# STM32H730 register map
File version: 1.9
CPU: CM7 r0p1, little endian, MPU, FPU, 4 interrupt priority bits
Registers are 32-bit, read-write, reset 0x0 unless marked. A register's access mark holds for its fields unless they carry their own. Offsets are from the block's base; [hi:lo] are bit positions; {n}, {i} and the like mark numbered series; 'fields as' and 'values as' point back to an identical list.

## BDMA
Base 0x58025400
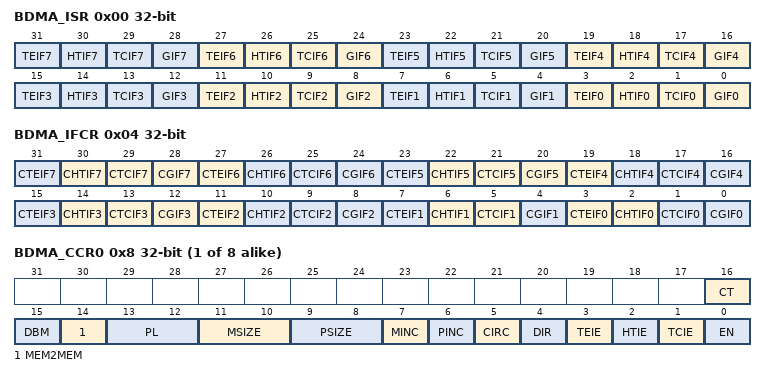
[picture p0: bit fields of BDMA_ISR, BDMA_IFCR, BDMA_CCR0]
0x00 BDMA_ISR ro — BDMA interrupt status register
  [4n+3] TEIF{n} (n=0..7) — transfer error (TE) flag for channel {n}
    0=no TE event; 1=a TE event occurred
  [4n+2] HTIF{n} (n=0..7) — half transfer (HT) flag for channel {n}
    0=no HT event; 1=a HT event occurred
  [4n+1] TCIF{n} (n=0..7) — transfer complete (TC) flag for channel {n}
    0=no TC event; 1=a TC event occurred
  [4n] GIF{n} (n=0..7) — global interrupt flag for channel {n}
    0=no TE, HT or TC event; 1=a TE, HT or TC event occurred
0x04 BDMA_IFCR wo — BDMA interrupt flag clear register
  [4n+3] CTEIF{n} (n=0..7) — transfer error flag clear for channel {n}
  [4n+2] CHTIF{n} (n=3..7) — half transfer flag clear for channel {n}
  [4n+1] CTCIF{n} (n=0..7) — transfer complete flag clear for channel {n}
  [4n] CGIF{n} (n=2..7) — global interrupt flag clear for channel {n}
  [10] CHTIF2 — half transfer flag clear for channe2
  [6] CHTIF1 — half transfer flag clear for channel 1
  [4] CGIF1 — global interrupt flag clear for channel 0
  [2] CHTIF0 — half transfer flag clear for channel 0
  [0] CGIF0 — global interrupt flag clear for channel 0
{0x8+0x14*i} BDMA_CCR{i} (i=0..7) — BDMA channel {i} configuration register
  [16] CT — current target memory of DMA transfer in double-buffer mode This bit is toggled by hardware at the end of each channel transfer in double-buffer mode. Note: this bit is set and cleared by software. It must not be written when the channel is enabled (EN = 1). It is read-only when the channel is enabled (EN = 1).
    0=memory 0 (addressed by the BDMA_CM0AR pointer); 1=memory 1 (addressed by the BDMA_CM1AR pointer)
  [15] DBM — double-buffer mode This bit must be set only in memory-to-peripheral and peripheral-to-memory transfers (MEM2MEM=0). The CIRC bit must also be set in double buffer mode. Note: this bit is set and cleared by software. It must not be written when the channel is enabled (EN = 1). It is not read-only when the channel is enabled (EN = 1).
    0=disabled (no memory address switch at the end of the BDMA transfer); 1=enabled (memory address switched at the end of the BDMA transfer)
  [14] MEM2MEM — memory-to-memory mode Note: this bit is set and cleared by software. It must not be written when the channel is enabled (EN = 1). It is read-only when the channel is enabled (EN = 1).
    0=disabled; 1=enabled
  [13:12] PL — priority level Note: this field is set and cleared by software. It must not be written when the channel is enabled (EN = 1). It is read-only when the channel is enabled (EN = 1).
    0=low; 1=medium; 2=high; 3=very high
  [11:10] MSIZE — memory size Defines the data size of each DMA transfer to the identified memory. In memory-to-memory mode, this field identifies the memory source if DIR = 1 and the memory destination if DIR = 0. In peripheral-to-peripheral mode, this field identifies the peripheral source if DIR = 1 and the peripheral destination if DIR = 0. Note: this field is set and cleared by software. It must not be written when the channel is enabled (EN = 1). It is read-only when the channel is enabled (EN = 1).
    0=8 bits; 1=16 bits; 2=32 bits
  [9:8] PSIZE — peripheral size Defines the data size of each DMA transfer to the identified peripheral. In memory-to-memory mode, this field identifies the memory destination if DIR = 1 and the memory source if DIR = 0. In peripheral-to-peripheral mode, this field identifies the peripheral destination if DIR = 1 and the peripheral source if DIR = 0. Note: this field is set and cleared by software. It must not be written when the channel is enabled (EN = 1). It is read-only when the channel is enabled (EN = 1).
    0=8 bits; 1=16 bits; 2=32 bits
  [7] MINC — memory increment mode Defines the increment mode for each DMA transfer to the identified memory. In memory-to-memory mode, this field identifies the memory source if DIR = 1 and the memory destination if DIR = 0. In peripheral-to-peripheral mode, this field identifies the peripheral source if DIR = 1 and the peripheral destination if DIR = 0. Note: this bit is set and cleared by software. It must not be written when the channel is enabled (EN = 1). It is read-only when the channel is enabled (EN = 1).
    0=disabled; 1=enabled
  [6] PINC — peripheral increment mode Defines the increment mode for each DMA transfer to the identified peripheral. n memory-to-memory mode, this field identifies the memory destination if DIR = 1 and the memory source if DIR = 0. In peripheral-to-peripheral mode, this field identifies the peripheral destination if DIR = 1 and the peripheral source if DIR = 0. Note: this bit is set and cleared by software. It must not be written when the channel is enabled (EN = 1). It is read-only when the channel is enabled (EN = 1).
    0=disabled; 1=enabled
  [5] CIRC — circular mode Note: this bit is set and cleared by software. It must not be written when the channel is enabled (EN = 1). It is not read-only when the channel is enabled (EN = 1).
    0=disabled; 1=enabled
  [4] DIR — data transfer direction This bit must be set only in memory-to-peripheral and peripheral-to-memory modes. Source attributes are defined by PSIZE and PINC, plus the BDMA_CPARx register. This is still valid in a memory-to-memory mode. Destination attributes are defined by MSIZE and MINC, plus the BDMA_CM0/1ARx register. This is still valid in a peripheral-to-peripheral mode. Destination attributes are defined by PSIZE and PINC, plus the BDMA_CPARx register. This is still valid in a memory-to-memory mode. Source attributes are defined by MSIZE and MINC, plus the BDMA_CM0/1ARx register. This is still valid in a peripheral-to-peripheral mode. Note: this bit is set and cleared by software. It must not be written when the channel is enabled (EN = 1). It is read-only when the channel is enabled (EN = 1).
    0=read from peripheral; 1=read from memory
  [3] TEIE — transfer error interrupt enable Note: this bit is set and cleared by software. It must not be written when the channel is enabled (EN = 1). It is not read-only when the channel is enabled (EN = 1).
    0=disabled; 1=enabled
  [2] HTIE — half transfer interrupt enable Note: this bit is set and cleared by software. It must not be written when the channel is enabled (EN = 1). It is not read-only when the channel is enabled (EN = 1).
    0=disabled; 1=enabled
  [1] TCIE — transfer complete interrupt enable Note: this bit is set and cleared by software. It must not be written when the channel is enabled (EN = 1). It is not read-only when the channel is enabled (EN = 1).
    0=disabled; 1=enabled
  [0] EN — channel enable When a channel transfer error occurs, this bit is cleared by hardware. It can not be set again by software (channel x re-activated) until the TEIFx bit of the BDMA_ISR register is cleared (by setting the CTEIFx bit of the BDMA_IFCR register). Note: this bit is set and cleared by software.
    0=disabled; 1=enabled
{0xC+0x14*i} BDMA_CNDTR{i} (i=0..7)
  [15:0] NDT — number of data to transfer (0 to 216 - 1) This field is updated by hardware when the channel is enabled: It is decremented after each single BDMA 'read followed by write' transfer, indicating the remaining amount of data items to transfer. It is kept at zero when the programmed amount of data to transfer is reached, if the channel is not in circular mode (CIRC = 0 in the BDMA_CCRx register). It is reloaded automatically by the previously programmed value, when the transfer is complete, if the channel is in circular mode (CIRC = 1). If this field is zero, no transfer can be served whatever the channel status (enabled or not). Note: this field is set and cleared by software. It must not be written when the channel is enabled (EN = 1). It is read-only when the channel is enabled (EN = 1).
{0x10+0x14*i} BDMA_CPAR{i} (i=0..7)
  [31:0] PA — peripheral address It contains the base address of the peripheral data register from/to which the data is read/written. When PSIZE[1:0] = 01 (16 bits), bit 0 of PA[31:0] is ignored. Access is automatically aligned to a half-word address. When PSIZE = 10 (32 bits), bits 1 and 0 of PA[31:0] are ignored. Access is automatically aligned to a word address. In memory-to-memory mode, this register identifies the memory destination address if DIR = 1 and the memory source address if DIR = 0. In peripheral-to-peripheral mode, this register identifies the peripheral destination address DIR = 1 and the peripheral source address if DIR = 0. Note: this register is set and cleared by software. It must not be written when the channel is enabled (EN = 1). It is not read-only when the channel is enabled (EN = 1).
{0x14+0x14*i} BDMA_CM0AR{i} (i=0..7)
  [31:0] MA — peripheral address It contains the base address of the memory from/to which the data is read/written. When MSIZE[1:0] = 01 (16 bits), bit 0 of MA[31:0] is ignored. Access is automatically aligned to a half-word address. When MSIZE = 10 (32 bits), bits 1 and 0 of MA[31:0] are ignored. Access is automatically aligned to a word address. In memory-to-memory mode, this register identifies the memory source address if DIR = 1 and the memory destination address if DIR = 0. In peripheral-to-peripheral mode, this register identifies the peripheral source address DIR = 1 and the peripheral destination address if DIR = 0. Note: this register is set and cleared by software. It must not be written when the channel is enabled (EN = 1). It is not read-only when the channel is enabled (EN = 1).
{0x18+0x14*i} BDMA_CM1AR{i} (i=0..7)
  fields as BDMA_CM0AR0

## Notices in the file
Copyright (c) 2025 STMicroelectronics.
SPDX-License-Identifier: Apache-2.0
Licensed under the Apache License, Version 2.0 (the "License");
you may not use this file except in compliance with the License.
You may obtain a copy of the License at
http://www.apache.org/licenses/LICENSE-2.0
Unless required by applicable law or agreed to in writing, software
distributed under the License is distributed on an "AS IS" BASIS,
WITHOUT WARRANTIES OR CONDITIONS OF ANY KIND, either express or implied.
See the License for the specific language governing permissions and
limitations under the License.
